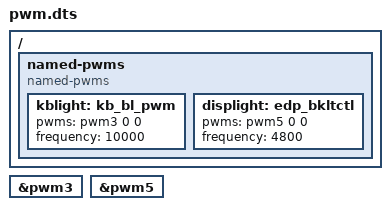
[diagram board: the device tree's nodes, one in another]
/* Copyright 2022 The Chromium OS Authors. All rights reserved.
 * Use of this source code is governed by a BSD-style license that can be
 * found in the LICENSE file.
 */

/ {
	named-pwms {
		compatible = "named-pwms";

		kblight: kb_bl_pwm {
			pwms = <&pwm3 0 0>;
			frequency = <10000>;
		};
		displight: edp_bkltctl {
			pwms = <&pwm5 0 0>;
			frequency = <4800>;
		};
	};
};

/* Keyboard backlight */
&pwm3 {
	status = "okay";
};

/* Display backlight */
&pwm5 {
	status = "okay";
};
